AUTOSAR XML (schema 4-2-2)
package /STELLANTIS/EPT/SASWCs
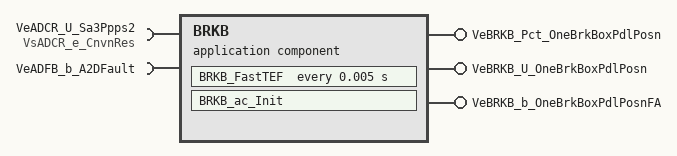
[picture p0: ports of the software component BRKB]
  application sw component type BRKB
    require port VeADCR_U_Sa3Ppps2: variation-point={short-label=vpVeADCR_U_Sa3Ppps2, sw-syscond=1}, nonqueued-receiver-com-spec{data-element=VsADCR_e_CnvnRes, init-value={short-label=DefaultInitValue_IDTRAdcInpResData, fields=[0, 0]}}, required-interface=VsADCR_e_CnvnRes
    require port VeADFB_b_A2DFault: variation-point={short-label=vpVeADFB_b_A2DFault, sw-syscond=1}, nonqueued-receiver-com-spec{data-element=Value, init-value=0}, required-interface=VeADFB_b_A2DFault
    provide port VeBRKB_Pct_OneBrkBoxPdlPosn: variation-point={short-label=vpVeBRKB_Pct_OneBrkBoxPdlPosn, sw-syscond=1}, nonqueued-sender-com-spec{data-element=Value, init-value=0}, provided-interface=VeBRKB_Pct_OneBrkBoxPdlPosn
    provide port VeBRKB_U_OneBrkBoxPdlPosn: variation-point={short-label=vpVeBRKB_U_OneBrkBoxPdlPosn, sw-syscond=1}, nonqueued-sender-com-spec{data-element=Value, init-value=0}, provided-interface=VeBRKB_U_OneBrkBoxPdlPosn
    provide port VeBRKB_b_OneBrkBoxPdlPosnFA: variation-point={short-label=vpVeBRKB_b_OneBrkBoxPdlPosnFA, sw-syscond=1}, nonqueued-sender-com-spec{data-element=Value, init-value=0}, provided-interface=VeBRKB_b_OneBrkBoxPdlPosnFA
    behavior IB_BRKB: data-type-mapping=[msADTtoIDTMapping, ADTtoIDTMapping], handle-termination-and-restart=NO-SUPPORT
      timing event Event_FastTEF: start-on-event=BRKB_FastTEF, period=0.005
      init event Event_BRKB_ac_Init: start-on-event=BRKB_ac_Init
      runnable BRKB_ac_Init
        data-send-points:
          access OUT_VeBRKB_Pct_OneBrkBoxPdlPosn_Value: accessed-variable=VeBRKB_Pct_OneBrkBoxPdlPosn.Value, variation-point={short-label=vpOUT_VeBRKB_Pct_OneBrkBoxPdlPosn_Value, sw-syscond=1}
          access OUT_VeBRKB_U_OneBrkBoxPdlPosn_Value: accessed-variable=VeBRKB_U_OneBrkBoxPdlPosn.Value, variation-point={short-label=vpOUT_VeBRKB_U_OneBrkBoxPdlPosn_Value, sw-syscond=1}
      runnable BRKB_FastTEF
        data-receive-point-by-arguments:
          access IN_VeADCR_U_Sa3Ppps2_VsADCR_e_CnvnRes: accessed-variable=VeADCR_U_Sa3Ppps2.VsADCR_e_CnvnRes, variation-point={short-label=vpIN_VeADCR_U_Sa3Ppps2_VsADCR_e_CnvnRes, sw-syscond=1}
          access IN_VeADFB_b_A2DFault_Value: accessed-variable=VeADFB_b_A2DFault.Value, variation-point={short-label=vpIN_VeADFB_b_A2DFault_Value, sw-syscond=1}
        data-send-points:
          access OUT_VeBRKB_Pct_OneBrkBoxPdlPosn_Value: accessed-variable=VeBRKB_Pct_OneBrkBoxPdlPosn.Value, variation-point={short-label=vpOUT_VeBRKB_Pct_OneBrkBoxPdlPosn_Value, sw-syscond=1}
          access OUT_VeBRKB_U_OneBrkBoxPdlPosn_Value: accessed-variable=VeBRKB_U_OneBrkBoxPdlPosn.Value, variation-point={short-label=vpOUT_VeBRKB_U_OneBrkBoxPdlPosn_Value, sw-syscond=1}
          access OUT_VeBRKB_b_OneBrkBoxPdlPosnFA_Value: accessed-variable=VeBRKB_b_OneBrkBoxPdlPosnFA.Value, variation-point={short-label=vpOUT_VeBRKB_b_OneBrkBoxPdlPosnFA_Value, sw-syscond=1}
      variation point proxy Variant_BRKB_HBO_Presence: category=CONDITION, condition-access=0
      variation point proxy Variant_BRKB_ONEBRKBOXSW_Presence: category=CONDITION, condition-access=1
